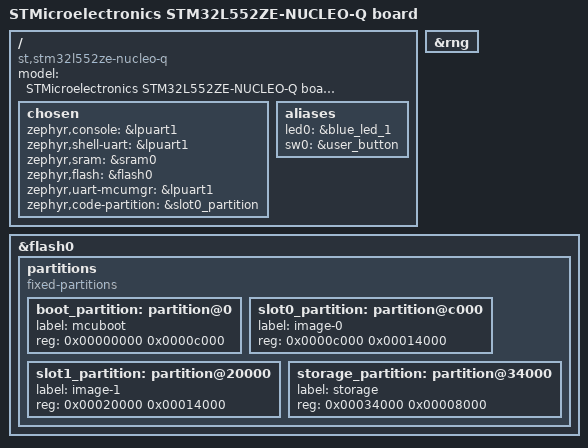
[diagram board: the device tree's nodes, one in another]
/*
 * Copyright (c) 2020 Linaro Limited
 *
 * SPDX-License-Identifier: Apache-2.0
 */

/dts-v1/;
#include "nucleo_l552ze_q-common.dtsi"

/ {
	model = "STMicroelectronics STM32L552ZE-NUCLEO-Q board";
	compatible = "st,stm32l552ze-nucleo-q";

	#address-cells = <1>;
	#size-cells = <1>;

	chosen {
		zephyr,console = &lpuart1;
		zephyr,shell-uart = &lpuart1;
		zephyr,sram = &sram0;
		zephyr,flash = &flash0;
		zephyr,uart-mcumgr = &lpuart1;
		zephyr,code-partition = &slot0_partition;
	};

	aliases {
		led0 = &blue_led_1;
		sw0 = &user_button;
	};
};

&rng {
	status = "okay";
};

&flash0 {
	partitions {
		compatible = "fixed-partitions";
		#address-cells = <1>;
		#size-cells = <1>;
		ranges;

		boot_partition: partition@0 {
			label = "mcuboot";
			reg = <0x00000000 0x0000c000>;
		};

		slot0_partition: partition@c000 {
			label = "image-0";
			reg = <0x0000c000 0x00014000>;
		};

		slot1_partition: partition@20000 {
			label = "image-1";
			reg = <0x00020000 0x00014000>;
		};

		storage_partition: partition@34000 {
			label = "storage";
			reg = <0x00034000 0x00008000>;
		};
	};
};
